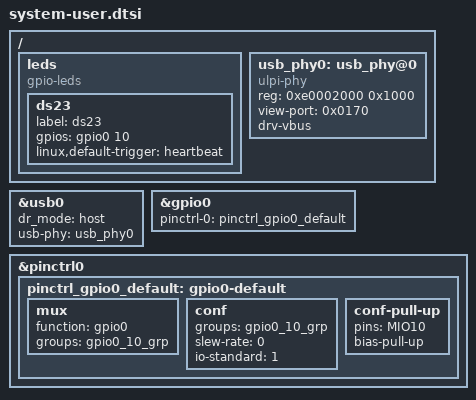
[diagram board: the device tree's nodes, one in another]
/include/ "system-conf.dtsi"
/ {
	leds {
		compatible = "gpio-leds";

		ds23 {
			label = "ds23";
			gpios = <&gpio0 10 0>;
			linux,default-trigger = "heartbeat";
		};
	};

	usb_phy0: usb_phy@0 {
		compatible = "ulpi-phy";
		#phy-cells = <0>;
		reg = <0xe0002000 0x1000>;
		view-port = <0x0170>;
		drv-vbus;
	};

};

&usb0 {
	dr_mode = "host";
	usb-phy = <&usb_phy0>;
};


&gpio0 {
	pinctrl-names = "default";
	pinctrl-0 = <&pinctrl_gpio0_default>;
};


&pinctrl0 {
	pinctrl_gpio0_default: gpio0-default {
		mux {
			function = "gpio0";
			groups = "gpio0_10_grp";
		};

		conf {
			groups = "gpio0_10_grp";
			slew-rate = <0>;
			io-standard = <1>;
		};

		conf-pull-up {
			pins = "MIO10";
			bias-pull-up;
		};
	};
};


